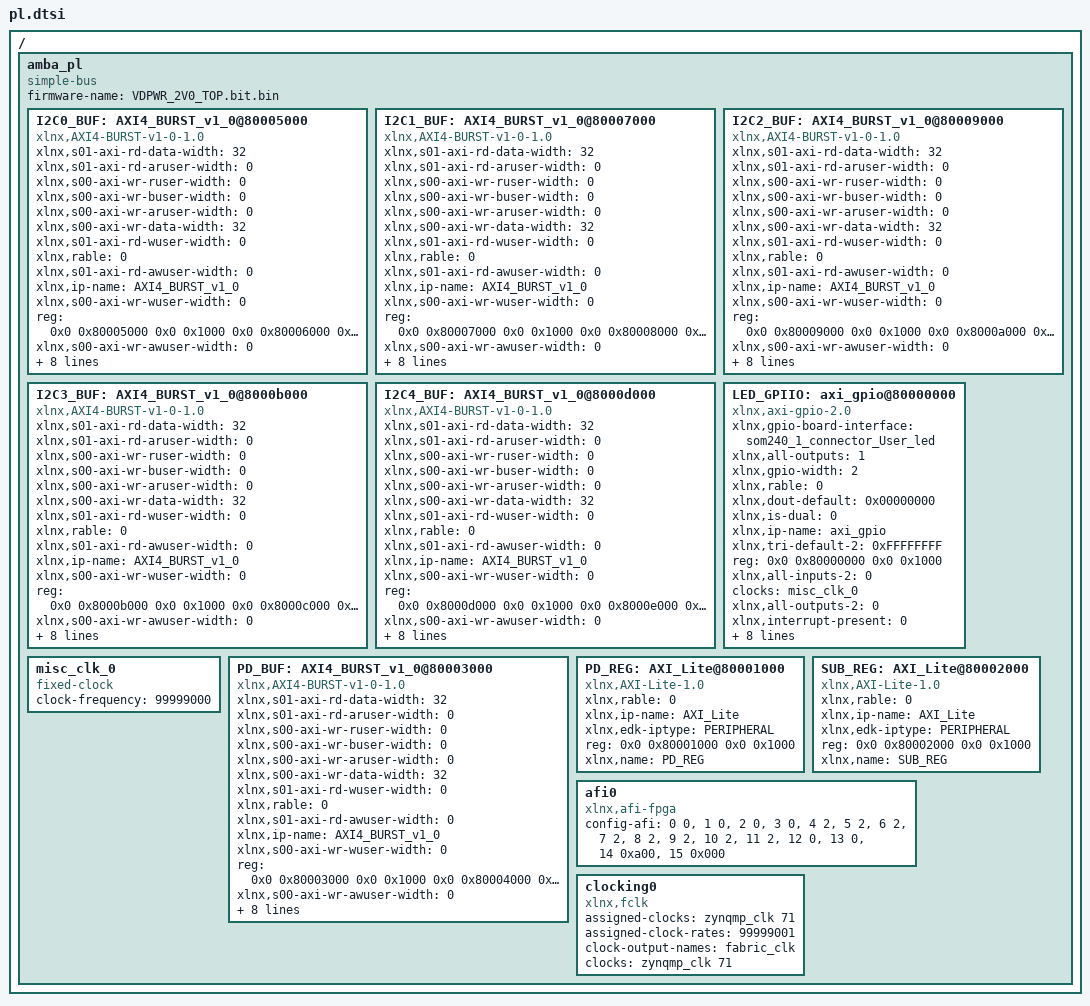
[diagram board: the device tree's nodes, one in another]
/ {
	amba_pl: amba_pl {
		ranges;
		compatible = "simple-bus";
		#address-cells = <2>;
		#size-cells = <2>;
		firmware-name = "VDPWR_2V0_TOP.bit.bin";
		I2C0_BUF: AXI4_BURST_v1_0@80005000 {
			xlnx,s01-axi-rd-data-width = <32>;
			xlnx,s01-axi-rd-aruser-width = <0>;
			compatible = "xlnx,AXI4-BURST-v1-0-1.0";
			xlnx,s00-axi-wr-ruser-width = <0>;
			xlnx,s00-axi-wr-buser-width = <0>;
			xlnx,s00-axi-wr-aruser-width = <0>;
			xlnx,s00-axi-wr-data-width = <32>;
			xlnx,s01-axi-rd-wuser-width = <0>;
			xlnx,rable = <0>;
			xlnx,s01-axi-rd-awuser-width = <0>;
			xlnx,ip-name = "AXI4_BURST_v1_0";
			xlnx,s00-axi-wr-wuser-width = <0>;
			reg = <0x0 0x80005000 0x0 0x1000 0x0 0x80006000 0x0 0x1000>;
			xlnx,s00-axi-wr-awuser-width = <0>;
			xlnx,s01-axi-rd-addr-width = <10>;
			xlnx,edk-iptype = "PERIPHERAL";
			xlnx,s01-axi-rd-id-width = <1>;
			xlnx,s00-axi-wr-addr-width = <10>;
			status = "okay";
			xlnx,s00-axi-wr-id-width = <1>;
			xlnx,s01-axi-rd-ruser-width = <0>;
			xlnx,s01-axi-rd-buser-width = <0>;
			xlnx,name = "I2C0_BUF";
		};
		I2C1_BUF: AXI4_BURST_v1_0@80007000 {
			xlnx,s01-axi-rd-data-width = <32>;
			xlnx,s01-axi-rd-aruser-width = <0>;
			compatible = "xlnx,AXI4-BURST-v1-0-1.0";
			xlnx,s00-axi-wr-ruser-width = <0>;
			xlnx,s00-axi-wr-buser-width = <0>;
			xlnx,s00-axi-wr-aruser-width = <0>;
			xlnx,s00-axi-wr-data-width = <32>;
			xlnx,s01-axi-rd-wuser-width = <0>;
			xlnx,rable = <0>;
			xlnx,s01-axi-rd-awuser-width = <0>;
			xlnx,ip-name = "AXI4_BURST_v1_0";
			xlnx,s00-axi-wr-wuser-width = <0>;
			reg = <0x0 0x80007000 0x0 0x1000 0x0 0x80008000 0x0 0x1000>;
			xlnx,s00-axi-wr-awuser-width = <0>;
			xlnx,s01-axi-rd-addr-width = <10>;
			xlnx,edk-iptype = "PERIPHERAL";
			xlnx,s01-axi-rd-id-width = <1>;
			xlnx,s00-axi-wr-addr-width = <10>;
			status = "okay";
			xlnx,s00-axi-wr-id-width = <1>;
			xlnx,s01-axi-rd-ruser-width = <0>;
			xlnx,s01-axi-rd-buser-width = <0>;
			xlnx,name = "I2C1_BUF";
		};
		I2C2_BUF: AXI4_BURST_v1_0@80009000 {
			xlnx,s01-axi-rd-data-width = <32>;
			xlnx,s01-axi-rd-aruser-width = <0>;
			compatible = "xlnx,AXI4-BURST-v1-0-1.0";
			xlnx,s00-axi-wr-ruser-width = <0>;
			xlnx,s00-axi-wr-buser-width = <0>;
			xlnx,s00-axi-wr-aruser-width = <0>;
			xlnx,s00-axi-wr-data-width = <32>;
			xlnx,s01-axi-rd-wuser-width = <0>;
			xlnx,rable = <0>;
			xlnx,s01-axi-rd-awuser-width = <0>;
			xlnx,ip-name = "AXI4_BURST_v1_0";
			xlnx,s00-axi-wr-wuser-width = <0>;
			reg = <0x0 0x80009000 0x0 0x1000 0x0 0x8000a000 0x0 0x1000>;
			xlnx,s00-axi-wr-awuser-width = <0>;
			xlnx,s01-axi-rd-addr-width = <10>;
			xlnx,edk-iptype = "PERIPHERAL";
			xlnx,s01-axi-rd-id-width = <1>;
			xlnx,s00-axi-wr-addr-width = <10>;
			status = "okay";
			xlnx,s00-axi-wr-id-width = <1>;
			xlnx,s01-axi-rd-ruser-width = <0>;
			xlnx,s01-axi-rd-buser-width = <0>;
			xlnx,name = "I2C2_BUF";
		};
		I2C3_BUF: AXI4_BURST_v1_0@8000b000 {
			xlnx,s01-axi-rd-data-width = <32>;
			xlnx,s01-axi-rd-aruser-width = <0>;
			compatible = "xlnx,AXI4-BURST-v1-0-1.0";
			xlnx,s00-axi-wr-ruser-width = <0>;
			xlnx,s00-axi-wr-buser-width = <0>;
			xlnx,s00-axi-wr-aruser-width = <0>;
			xlnx,s00-axi-wr-data-width = <32>;
			xlnx,s01-axi-rd-wuser-width = <0>;
			xlnx,rable = <0>;
			xlnx,s01-axi-rd-awuser-width = <0>;
			xlnx,ip-name = "AXI4_BURST_v1_0";
			xlnx,s00-axi-wr-wuser-width = <0>;
			reg = <0x0 0x8000b000 0x0 0x1000 0x0 0x8000c000 0x0 0x1000>;
			xlnx,s00-axi-wr-awuser-width = <0>;
			xlnx,s01-axi-rd-addr-width = <10>;
			xlnx,edk-iptype = "PERIPHERAL";
			xlnx,s01-axi-rd-id-width = <1>;
			xlnx,s00-axi-wr-addr-width = <10>;
			status = "okay";
			xlnx,s00-axi-wr-id-width = <1>;
			xlnx,s01-axi-rd-ruser-width = <0>;
			xlnx,s01-axi-rd-buser-width = <0>;
			xlnx,name = "I2C3_BUF";
		};
		I2C4_BUF: AXI4_BURST_v1_0@8000d000 {
			xlnx,s01-axi-rd-data-width = <32>;
			xlnx,s01-axi-rd-aruser-width = <0>;
			compatible = "xlnx,AXI4-BURST-v1-0-1.0";
			xlnx,s00-axi-wr-ruser-width = <0>;
			xlnx,s00-axi-wr-buser-width = <0>;
			xlnx,s00-axi-wr-aruser-width = <0>;
			xlnx,s00-axi-wr-data-width = <32>;
			xlnx,s01-axi-rd-wuser-width = <0>;
			xlnx,rable = <0>;
			xlnx,s01-axi-rd-awuser-width = <0>;
			xlnx,ip-name = "AXI4_BURST_v1_0";
			xlnx,s00-axi-wr-wuser-width = <0>;
			reg = <0x0 0x8000d000 0x0 0x1000 0x0 0x8000e000 0x0 0x1000>;
			xlnx,s00-axi-wr-awuser-width = <0>;
			xlnx,s01-axi-rd-addr-width = <10>;
			xlnx,edk-iptype = "PERIPHERAL";
			xlnx,s01-axi-rd-id-width = <1>;
			xlnx,s00-axi-wr-addr-width = <10>;
			status = "okay";
			xlnx,s00-axi-wr-id-width = <1>;
			xlnx,s01-axi-rd-ruser-width = <0>;
			xlnx,s01-axi-rd-buser-width = <0>;
			xlnx,name = "I2C4_BUF";
		};
		LED_GPIIO: axi_gpio@80000000 {
			xlnx,gpio-board-interface = "som240_1_connector_User_led";
			compatible = "xlnx,axi-gpio-2.0" , "xlnx,xps-gpio-1.00.a";
			xlnx,all-outputs = <1>;
			xlnx,gpio-width = <2>;
			xlnx,rable = <0>;
			xlnx,dout-default = <0x00000000>;
			xlnx,is-dual = <0>;
			xlnx,ip-name = "axi_gpio";
			xlnx,tri-default-2 = <0xFFFFFFFF>;
			reg = <0x0 0x80000000 0x0 0x1000>;
			xlnx,all-inputs-2 = <0>;
			clocks = <&misc_clk_0>;
			xlnx,all-outputs-2 = <0>;
			xlnx,interrupt-present = <0>;
			xlnx,gpio2-board-interface = "Custom";
			xlnx,edk-iptype = "PERIPHERAL";
			xlnx,dout-default-2 = <0x00000000>;
			xlnx,gpio2-width = <1>;
			status = "okay";
			clock-names = "s_axi_aclk";
			xlnx,use-board-flow;
			xlnx,tri-default = <0xFFFFFFFF>;
			xlnx,name = "LED_GPIIO";
			xlnx,all-inputs = <0>;
		};
		misc_clk_0: misc_clk_0 {
			compatible = "fixed-clock";
			clock-frequency = <99999000>;
			#clock-cells = <0>;
		};
		PD_BUF: AXI4_BURST_v1_0@80003000 {
			xlnx,s01-axi-rd-data-width = <32>;
			xlnx,s01-axi-rd-aruser-width = <0>;
			compatible = "xlnx,AXI4-BURST-v1-0-1.0";
			xlnx,s00-axi-wr-ruser-width = <0>;
			xlnx,s00-axi-wr-buser-width = <0>;
			xlnx,s00-axi-wr-aruser-width = <0>;
			xlnx,s00-axi-wr-data-width = <32>;
			xlnx,s01-axi-rd-wuser-width = <0>;
			xlnx,rable = <0>;
			xlnx,s01-axi-rd-awuser-width = <0>;
			xlnx,ip-name = "AXI4_BURST_v1_0";
			xlnx,s00-axi-wr-wuser-width = <0>;
			reg = <0x0 0x80003000 0x0 0x1000 0x0 0x80004000 0x0 0x1000>;
			xlnx,s00-axi-wr-awuser-width = <0>;
			xlnx,s01-axi-rd-addr-width = <10>;
			xlnx,edk-iptype = "PERIPHERAL";
			xlnx,s01-axi-rd-id-width = <1>;
			xlnx,s00-axi-wr-addr-width = <10>;
			status = "okay";
			xlnx,s00-axi-wr-id-width = <1>;
			xlnx,s01-axi-rd-ruser-width = <0>;
			xlnx,s01-axi-rd-buser-width = <0>;
			xlnx,name = "PD_BUF";
		};
		PD_REG: AXI_Lite@80001000 {
			xlnx,rable = <0>;
			compatible = "xlnx,AXI-Lite-1.0";
			status = "okay";
			xlnx,ip-name = "AXI_Lite";
			xlnx,edk-iptype = "PERIPHERAL";
			reg = <0x0 0x80001000 0x0 0x1000>;
			xlnx,name = "PD_REG";
		};
		SUB_REG: AXI_Lite@80002000 {
			xlnx,rable = <0>;
			compatible = "xlnx,AXI-Lite-1.0";
			status = "okay";
			xlnx,ip-name = "AXI_Lite";
			xlnx,edk-iptype = "PERIPHERAL";
			reg = <0x0 0x80002000 0x0 0x1000>;
			xlnx,name = "SUB_REG";
		};
		afi0: afi0 {
			status = "okay";
			compatible = "xlnx,afi-fpga";
			config-afi = < 0 0>, <1 0>, <2 0>, <3 0>, <4 2>, <5 2>, <6 2>, <7 2>, <8 2>, <9 2>, <10 2>, <11 2>, <12 0>, <13 0>, <14 0xa00>, <15 0x000>;
		};
		clocking0: clocking0 {
			compatible = "xlnx,fclk";
			assigned-clocks = <&zynqmp_clk 71>;
			assigned-clock-rates = <99999001>;
			#clock-cells = <0>;
			clock-output-names = "fabric_clk";
			clocks = <&zynqmp_clk 71>;
		};
	};
};
